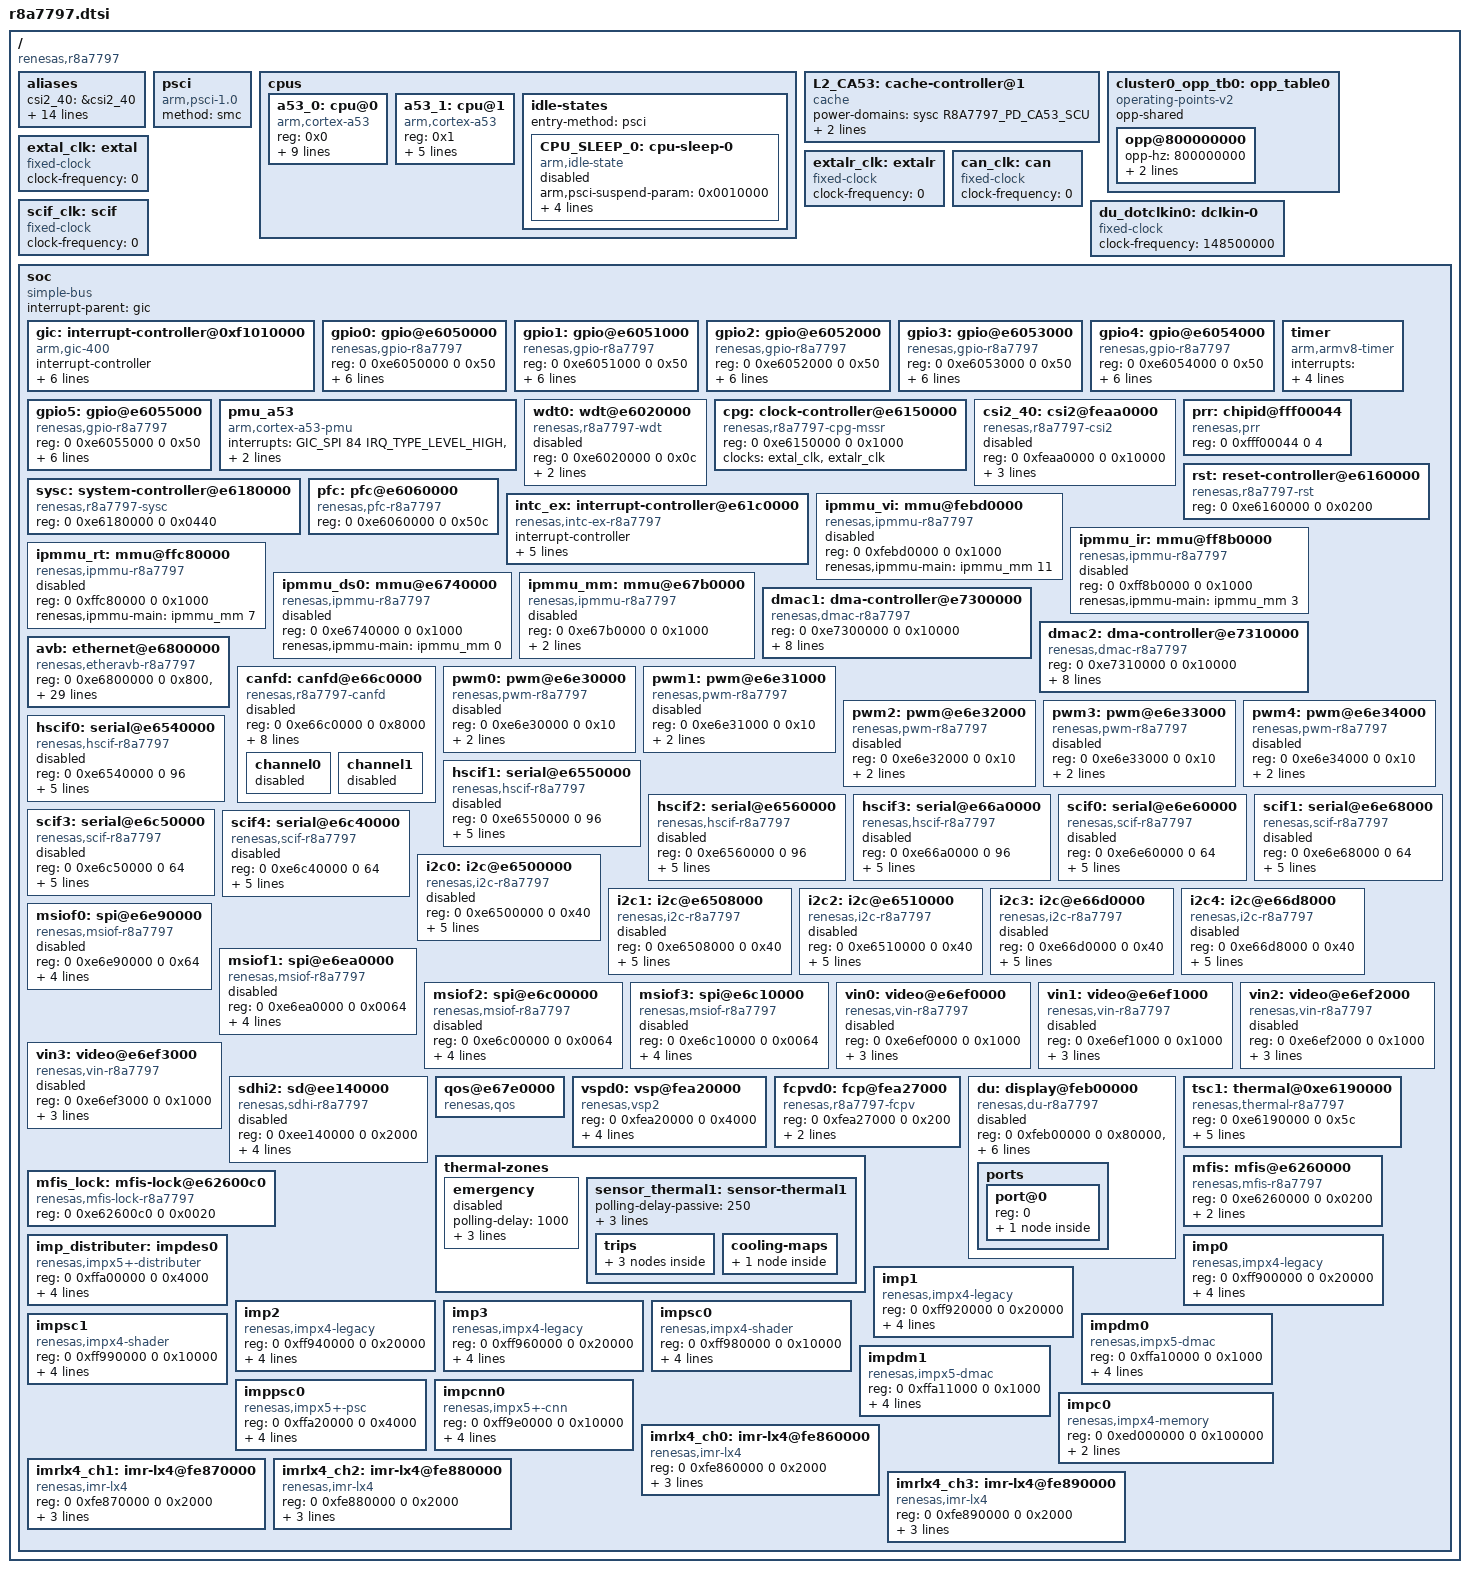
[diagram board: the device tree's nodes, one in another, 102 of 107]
/*
 * Device Tree Source for the r8a7797 SoC
 *
 * Copyright (C) 2016 - 2017 Renesas Electronics Corp.
 *
 * This file is licensed under the terms of the GNU General Public License
 * version 2.  This program is licensed "as is" without any warranty of any
 * kind, whether express or implied.
 */

#include <dt-bindings/clock/r8a7797-cpg-mssr.h>
#include <dt-bindings/interrupt-controller/arm-gic.h>
#include <dt-bindings/power/r8a7797-sysc.h>

/ {
	compatible = "renesas,r8a7797";
	#address-cells = <2>;
	#size-cells = <2>;

	aliases {
		csi2_40 = &csi2_40;
		i2c0 = &i2c0;
		i2c1 = &i2c1;
		i2c2 = &i2c2;
		i2c3 = &i2c3;
		i2c4 = &i2c4;
		spi1 = &msiof0;
		spi2 = &msiof1;
		spi3 = &msiof2;
		spi4 = &msiof3;
		vin0 = &vin0;
		vin1 = &vin1;
		vin2 = &vin2;
		vin3 = &vin3;
		tsc0 = &tsc1;
	};

	psci {
		compatible = "arm,psci-1.0";
		method = "smc";
	};

	cpus {
		#address-cells = <1>;
		#size-cells = <0>;

		a53_0: cpu@0 {
			compatible = "arm,cortex-a53", "arm,armv8";
			reg = <0x0>;
			device_type = "cpu";
			power-domains = <&sysc R8A7797_PD_CA53_CPU0>;
			next-level-cache = <&L2_CA53>;
			enable-method = "psci";
			cpu-idle-states = <&CPU_SLEEP_0>;
			#cooling-cells = <2>;
			dynamic-power-coefficient = <277>;
			cooling-min-level = <0>;
			cooling-max-level = <2>;
			clocks =<&cpg CPG_CORE R8A7797_CLK_Z2>;
			operating-points-v2 = <&cluster0_opp_tb0>;
			/*cpu-supply = <&vdd_dvfs>;*/
		};

		a53_1: cpu@1 {
			compatible = "arm,cortex-a53","arm,armv8";
			reg = <0x1>;
			device_type = "cpu";
			power-domains = <&sysc R8A7797_PD_CA53_CPU1>;
			next-level-cache = <&L2_CA53>;
			enable-method = "psci";
			cpu-idle-states = <&CPU_SLEEP_0>;
			operating-points-v2 = <&cluster0_opp_tb0>;
		};

		idle-states {
			entry-method = "psci";

			CPU_SLEEP_0: cpu-sleep-0 {
				compatible = "arm,idle-state";
				arm,psci-suspend-param = <0x0010000>;
				local-timer-stop;
				entry-latency-us = <639>;
				exit-latency-us = <680>;
				min-residency-us = <1088>;
				status = "disabled";
			};
		};
	};

	L2_CA53: cache-controller@1 {
		compatible = "cache";
		power-domains = <&sysc R8A7797_PD_CA53_SCU>;
		cache-unified;
		cache-level = <2>;
	};

	cluster0_opp_tb0: opp_table0 {
		compatible = "operating-points-v2";
		opp-shared;

		opp@800000000 {
			opp-hz = /bits/ 64 <800000000>;
			opp-microvolt = <850000>;
			clock-latency-ns = <300000>;
		};
	};

	extal_clk: extal {
		compatible = "fixed-clock";
		#clock-cells = <0>;
		/* This value must be overridden by the board */
		clock-frequency = <0>;
	};

	extalr_clk: extalr {
		compatible = "fixed-clock";
		#clock-cells = <0>;
		/* This value must be overridden by the board */
		clock-frequency = <0>;
	};

	/* External CAN clock - to be overridden by boards that provide it */
	can_clk: can {
		compatible = "fixed-clock";
		#clock-cells = <0>;
		clock-frequency = <0>;
	};

	/* External SCIF clock - to be overridden by boards that provide it */
	scif_clk: scif {
		compatible = "fixed-clock";
		#clock-cells = <0>;
		clock-frequency = <0>;
	};

	/* DU input dot clock - tob be overriden by boards that probide it */
	du_dotclkin0: dclkin-0 {
		compatible = "fixed-clock";
		#clock-cells = <0>;
		clock-frequency = <148500000>;
	};

	soc {
		compatible = "simple-bus";
		interrupt-parent = <&gic>;

		#address-cells = <2>;
		#size-cells = <2>;
		ranges;

		gic: interrupt-controller@0xf1010000 {
			compatible = "arm,gic-400";
			#interrupt-cells = <3>;
			#address-cells = <0>;
			interrupt-controller;
			reg = <0x0 0xf1010000 0 0x1000>,
			      <0x0 0xf1020000 0 0x20000>,
			      <0x0 0xf1040000 0 0x20000>,
			      <0x0 0xf1060000 0 0x20000>;
			interrupts = <GIC_PPI 9
					(GIC_CPU_MASK_SIMPLE(8) | IRQ_TYPE_LEVEL_HIGH)>;	/* PPI9:Virtual maintenance interrupt */
/*			clocks = <&cpg CPG_MOD 408>;
			clock-names = "clk";
			power-domains = <&sysc R8A7797_PD_ALWAYS_ON>; */
		};

		gpio0: gpio@e6050000 {
			compatible = "renesas,gpio-r8a7797",
				     "renesas,gpio-rcar";
			reg = <0 0xe6050000 0 0x50>;
			interrupts = <GIC_SPI 4 IRQ_TYPE_LEVEL_HIGH>;		/* SPI4:GPIO.ch0 */
			#gpio-cells = <2>;
			gpio-controller;
			gpio-ranges = <&pfc 0 0 22>;
			#interrupt-cells = <2>;
			interrupt-controller;
			clocks = <&cpg CPG_MOD 912>;				/* RMSTPCR9/bit12:GPIO0 */
			power-domains = <&sysc R8A7797_PD_ALWAYS_ON>;
		};

		gpio1: gpio@e6051000 {
			compatible = "renesas,gpio-r8a7797",
				     "renesas,gpio-rcar";
			reg = <0 0xe6051000 0 0x50>;
			interrupts = <GIC_SPI 5 IRQ_TYPE_LEVEL_HIGH>;		/* SPI5:GPIO.ch1 */
			#gpio-cells = <2>;
			gpio-controller;
			gpio-ranges = <&pfc 0 32 28>;
			#interrupt-cells = <2>;
			interrupt-controller;
			clocks = <&cpg CPG_MOD 911>;				/* RMSTPCR9/bit11:GPIO1 */
			power-domains = <&sysc R8A7797_PD_ALWAYS_ON>;
		};

		gpio2: gpio@e6052000 {
			compatible = "renesas,gpio-r8a7797",
				     "renesas,gpio-rcar";
			reg = <0 0xe6052000 0 0x50>;
			interrupts = <GIC_SPI 6 IRQ_TYPE_LEVEL_HIGH>;		/* SPI6:GPIO.ch2 */
			#gpio-cells = <2>;
			gpio-controller;
			gpio-ranges = <&pfc 0 64 17>;
			#interrupt-cells = <2>;
			interrupt-controller;
			clocks = <&cpg CPG_MOD 910>;				/* RMSTPCR9/bit10:GPIO2 */
			power-domains = <&sysc R8A7797_PD_ALWAYS_ON>;
		};

		gpio3: gpio@e6053000 {
			compatible = "renesas,gpio-r8a7797",
				     "renesas,gpio-rcar";
			reg = <0 0xe6053000 0 0x50>;
			interrupts = <GIC_SPI 7 IRQ_TYPE_LEVEL_HIGH>;		/* SPI7:GPIO.ch3 */
			#gpio-cells = <2>;
			gpio-controller;
			gpio-ranges = <&pfc 0 96 17>;
			#interrupt-cells = <2>;
			interrupt-controller;
			clocks = <&cpg CPG_MOD 909>;				/* RMSTPCR9/bit9:GPIO3 */
			power-domains = <&sysc R8A7797_PD_ALWAYS_ON>;
		};

		gpio4: gpio@e6054000 {
			compatible = "renesas,gpio-r8a7797",
				     "renesas,gpio-rcar";
			reg = <0 0xe6054000 0 0x50>;
			interrupts = <GIC_SPI 8 IRQ_TYPE_LEVEL_HIGH>;		/* SPI8:GPIO.ch4 */
			#gpio-cells = <2>;
			gpio-controller;
			gpio-ranges = <&pfc 0 128 6>;
			#interrupt-cells = <2>;
			interrupt-controller;
			clocks = <&cpg CPG_MOD 908>;				/* RMSTPCR9/bit8:GPIO4 */
			power-domains = <&sysc R8A7797_PD_ALWAYS_ON>;
		};

		gpio5: gpio@e6055000 {
			compatible = "renesas,gpio-r8a7797",
				     "renesas,gpio-rcar";
			reg = <0 0xe6055000 0 0x50>;
			interrupts = <GIC_SPI 9 IRQ_TYPE_LEVEL_HIGH>;		/* SPI9:GPIO.ch5 */
			#gpio-cells = <2>;
			gpio-controller;
			gpio-ranges = <&pfc 0 160 15>;
			#interrupt-cells = <2>;
			interrupt-controller;
			clocks = <&cpg CPG_MOD 907>;				/* RMSTPCR9/bit7:GPIO5 */
			power-domains = <&sysc R8A7797_PD_ALWAYS_ON>;
		};

		pmu_a53 {
			compatible = "arm,cortex-a53-pmu";
			interrupts = <GIC_SPI 84 IRQ_TYPE_LEVEL_HIGH>,
				     <GIC_SPI 85 IRQ_TYPE_LEVEL_HIGH>;		/* SPI84:AP-System Core.CA53core0 pmu, SPI85:AP-System Core.CA53core1 pmu */
			interrupt-affinity = <&a53_0>,
					     <&a53_1>;
		};

		timer {
			compatible = "arm,armv8-timer";
			interrupts = <GIC_PPI 13
					(GIC_CPU_MASK_SIMPLE(8) | IRQ_TYPE_LEVEL_LOW)>,
				     <GIC_PPI 14
					(GIC_CPU_MASK_SIMPLE(8) | IRQ_TYPE_LEVEL_LOW)>,
				     <GIC_PPI 11
					(GIC_CPU_MASK_SIMPLE(8) | IRQ_TYPE_LEVEL_LOW)>,
				     <GIC_PPI 10
					(GIC_CPU_MASK_SIMPLE(8) | IRQ_TYPE_LEVEL_LOW)>;	/* PPI13:Secure physical timer, PPI14:Non-secure physical timer,
																	   PPI11:Virtual timer, PPI10:Hypervisor timer */
		};

		wdt0: wdt@e6020000 {
			compatible = "renesas,r8a7797-wdt", "renesas,rcar-gen3-wdt";
			reg = <0 0xe6020000 0 0x0c>;
			clocks = <&cpg CPG_MOD 402>;					/* RMSTPCR4/bit2:RWDT */
			power-domains = <&sysc R8A7797_PD_ALWAYS_ON>;
			status = "disabled";
		};

		cpg: clock-controller@e6150000 {
			compatible = "renesas,r8a7797-cpg-mssr";
			reg = <0 0xe6150000 0 0x1000>;
			clocks = <&extal_clk>, <&extalr_clk>;
			clock-names = "extal", "extalr";
			#clock-cells = <2>;
			#power-domain-cells = <0>;
		};

		csi2_40: csi2@feaa0000 {
			compatible = "renesas,r8a7797-csi2";
			reg = <0 0xfeaa0000 0 0x10000>;
			interrupts = <GIC_SPI 246 IRQ_TYPE_LEVEL_HIGH>;		/* SPI246:CSI2.ch2 */
			clocks = <&cpg CPG_MOD 716>;				/* RMSTPCR7/bit16:CSI40 */
			power-domains = <&sysc R8A7797_PD_ALWAYS_ON>;
			status = "disabled";
		};

		prr: chipid@fff00044 {
			compatible = "renesas,prr";
			reg = <0 0xfff00044 0 4>;
		};

		rst: reset-controller@e6160000 {
			compatible = "renesas,r8a7797-rst";
			reg = <0 0xe6160000 0 0x0200>;
		};

		sysc: system-controller@e6180000 {
			compatible = "renesas,r8a7797-sysc";
			reg = <0 0xe6180000 0 0x0440>;
			#power-domain-cells = <1>;
		};

		pfc: pfc@e6060000 {
			compatible = "renesas,pfc-r8a7797";
			reg = <0 0xe6060000 0 0x50c>;
		};

		intc_ex: interrupt-controller@e61c0000 {
			compatible = "renesas,intc-ex-r8a7797", "renesas,irqc";
			#interrupt-cells = <2>;
			interrupt-controller;
			reg = <0 0xe61c0000 0 0x200>;
			interrupts = <GIC_SPI 0 IRQ_TYPE_LEVEL_HIGH
				      GIC_SPI 1 IRQ_TYPE_LEVEL_HIGH
				      GIC_SPI 2 IRQ_TYPE_LEVEL_HIGH
				      GIC_SPI 3 IRQ_TYPE_LEVEL_HIGH
				      GIC_SPI 18 IRQ_TYPE_LEVEL_HIGH
				      GIC_SPI 161 IRQ_TYPE_LEVEL_HIGH>;		/* SPI1:IRQ1, SPI2:IRQ2, SPI3:IRQ3, SPI18:IRQ4, SPI161:IRQ5 */
			clocks = <&cpg CPG_MOD 407>;				/* RMSTPCR4/bit7:INTC-EX */
			power-domains = <&sysc R8A7797_PD_ALWAYS_ON>;
		};

		ipmmu_vi: mmu@febd0000 {
			compatible = "renesas,ipmmu-r8a7797";
			reg = <0 0xfebd0000 0 0x1000>; /* IPMMU-VI */
			renesas,ipmmu-main = <&ipmmu_mm 11>;
			#iommu-cells = <1>;
			status = "disabled";
		};

		ipmmu_ir: mmu@ff8b0000 {
			compatible = "renesas,ipmmu-r8a7797";
			reg = <0 0xff8b0000 0 0x1000>; /* IPMMU-IR */
			renesas,ipmmu-main = <&ipmmu_mm 3>;
			#iommu-cells = <1>;
			status = "disabled";
		};

		ipmmu_rt: mmu@ffc80000 {
			compatible = "renesas,ipmmu-r8a7797";
			reg = <0 0xffc80000 0 0x1000>; /* IPMMU-RT */
			renesas,ipmmu-main = <&ipmmu_mm 7>;
			#iommu-cells = <1>;
			status = "disabled";
		};

		ipmmu_ds0: mmu@e6740000 {
			compatible = "renesas,ipmmu-r8a7797";
			reg = <0 0xe6740000 0 0x1000>; /* IPMMU-DS0 */
			renesas,ipmmu-main = <&ipmmu_mm 0>;
			#iommu-cells = <1>;
			status = "disabled";
		};

		ipmmu_mm: mmu@e67b0000 {
			compatible = "renesas,ipmmu-r8a7797";
			reg = <0 0xe67b0000 0 0x1000>; /* IPMMU-MM */
			interrupts = <GIC_SPI 196 IRQ_TYPE_LEVEL_HIGH>,
				     <GIC_SPI 197 IRQ_TYPE_LEVEL_HIGH>;		/* SPI196:IPMMU, SPI197:IPMMU sec */
			#iommu-cells = <1>;
			status = "disabled";
		};

		dmac1: dma-controller@e7300000 {
			compatible = "renesas,dmac-r8a7797",
				     "renesas,rcar-dmac";
			reg = <0 0xe7300000 0 0x10000>;
			interrupts = <GIC_SPI 220 IRQ_TYPE_LEVEL_HIGH
				      GIC_SPI 216 IRQ_TYPE_LEVEL_HIGH
				      GIC_SPI 217 IRQ_TYPE_LEVEL_HIGH
				      GIC_SPI 218 IRQ_TYPE_LEVEL_HIGH
				      GIC_SPI 219 IRQ_TYPE_LEVEL_HIGH
				      GIC_SPI 308 IRQ_TYPE_LEVEL_HIGH
				      GIC_SPI 309 IRQ_TYPE_LEVEL_HIGH
				      GIC_SPI 310 IRQ_TYPE_LEVEL_HIGH
				      GIC_SPI 311 IRQ_TYPE_LEVEL_HIGH>;		/* SPI220::SYS-DMAC1 err,
										   SPI216~219:SYS-DMAC1.ch0~SYS-DMAC1.ch3,
										   SPI308~311:SYS-DMAC1.ch4~SYS-DMAC1.ch7 */
			interrupt-names = "error",
					"ch0", "ch1", "ch2", "ch3",
					"ch4", "ch5", "ch6", "ch7";
			clocks = <&cpg CPG_MOD 218>;				/* RMSTPCR2/bit18:SYS-DMAC1 */
			clock-names = "fck";
			power-domains = <&sysc R8A7797_PD_ALWAYS_ON>;
			#dma-cells = <1>;
			dma-channels = <8>;
			iommus = <&ipmmu_ds0 0>, <&ipmmu_ds0 1>,
			       <&ipmmu_ds0 2>, <&ipmmu_ds0 3>,
			       <&ipmmu_ds0 4>, <&ipmmu_ds0 5>,
			       <&ipmmu_ds0 6>, <&ipmmu_ds0 7>;			/* @@ */
		};

		dmac2: dma-controller@e7310000 {
			compatible = "renesas,dmac-r8a7797",
				     "renesas,rcar-dmac";
			reg = <0 0xe7310000 0 0x10000>;
			interrupts = <GIC_SPI 307 IRQ_TYPE_LEVEL_HIGH
				      GIC_SPI 312 IRQ_TYPE_LEVEL_HIGH
				      GIC_SPI 313 IRQ_TYPE_LEVEL_HIGH
				      GIC_SPI 314 IRQ_TYPE_LEVEL_HIGH
				      GIC_SPI 315 IRQ_TYPE_LEVEL_HIGH
				      GIC_SPI 316 IRQ_TYPE_LEVEL_HIGH
				      GIC_SPI 317 IRQ_TYPE_LEVEL_HIGH
				      GIC_SPI 318 IRQ_TYPE_LEVEL_HIGH
				      GIC_SPI 319 IRQ_TYPE_LEVEL_HIGH>;		/* SPI307::SYS-DMAC2 err,
										   SPI312~319:SYS-DMAC2.ch0~SYS-DMAC1.ch7 */
			interrupt-names = "error",
					"ch0", "ch1", "ch2", "ch3",
					"ch4", "ch5", "ch6", "ch7";
			clocks = <&cpg CPG_MOD 217>;				/* RMSTPCR2/bit17:SYS-DMAC2 */
			clock-names = "fck";
			power-domains = <&sysc R8A7797_PD_ALWAYS_ON>;
			#dma-cells = <1>;
			dma-channels = <8>;
			iommus = <&ipmmu_ds0 16>, <&ipmmu_ds0 17>,
			       <&ipmmu_ds0 18>, <&ipmmu_ds0 19>,
			       <&ipmmu_ds0 20>, <&ipmmu_ds0 21>,
			       <&ipmmu_ds0 22>, <&ipmmu_ds0 23>;		/* @@ */
		};

		avb: ethernet@e6800000 {
			compatible = "renesas,etheravb-r8a7797",
				     "renesas,etheravb-rcar-gen3";
			reg = <0 0xe6800000 0 0x800>, <0 0xe6a00000 0 0x10000>;
			interrupts = <GIC_SPI 39 IRQ_TYPE_LEVEL_HIGH>,
				     <GIC_SPI 40 IRQ_TYPE_LEVEL_HIGH>,
				     <GIC_SPI 41 IRQ_TYPE_LEVEL_HIGH>,
				     <GIC_SPI 42 IRQ_TYPE_LEVEL_HIGH>,
				     <GIC_SPI 43 IRQ_TYPE_LEVEL_HIGH>,
				     <GIC_SPI 44 IRQ_TYPE_LEVEL_HIGH>,
				     <GIC_SPI 45 IRQ_TYPE_LEVEL_HIGH>,
				     <GIC_SPI 46 IRQ_TYPE_LEVEL_HIGH>,
				     <GIC_SPI 47 IRQ_TYPE_LEVEL_HIGH>,
				     <GIC_SPI 48 IRQ_TYPE_LEVEL_HIGH>,
				     <GIC_SPI 49 IRQ_TYPE_LEVEL_HIGH>,
				     <GIC_SPI 50 IRQ_TYPE_LEVEL_HIGH>,
				     <GIC_SPI 51 IRQ_TYPE_LEVEL_HIGH>,
				     <GIC_SPI 52 IRQ_TYPE_LEVEL_HIGH>,
				     <GIC_SPI 53 IRQ_TYPE_LEVEL_HIGH>,
				     <GIC_SPI 54 IRQ_TYPE_LEVEL_HIGH>,
				     <GIC_SPI 55 IRQ_TYPE_LEVEL_HIGH>,
				     <GIC_SPI 56 IRQ_TYPE_LEVEL_HIGH>,
				     <GIC_SPI 57 IRQ_TYPE_LEVEL_HIGH>,
				     <GIC_SPI 58 IRQ_TYPE_LEVEL_HIGH>,
				     <GIC_SPI 59 IRQ_TYPE_LEVEL_HIGH>,
				     <GIC_SPI 60 IRQ_TYPE_LEVEL_HIGH>,
				     <GIC_SPI 61 IRQ_TYPE_LEVEL_HIGH>,
				     <GIC_SPI 62 IRQ_TYPE_LEVEL_HIGH>,
				     <GIC_SPI 63 IRQ_TYPE_LEVEL_HIGH>;		/* SPI39~63:Ethernet AVB.ch0~24 */
										/* @@ errreq_avb_p[0]~[3] add (T.B.D) */
			interrupt-names = "ch0", "ch1", "ch2", "ch3",
					  "ch4", "ch5", "ch6", "ch7",
					  "ch8", "ch9", "ch10", "ch11",
					  "ch12", "ch13", "ch14", "ch15",
					  "ch16", "ch17", "ch18", "ch19",
					  "ch20", "ch21", "ch22", "ch23",
					  "ch24";
			clocks = <&cpg CPG_MOD 812>;				/* RMSTPCR8/bit12:EAVB-IF */
			power-domains = <&sysc R8A7797_PD_ALWAYS_ON>;
			phy-mode = "rgmii-id";
			#address-cells = <1>;
			#size-cells = <0>;
		};

		canfd: canfd@e66c0000 {
			compatible = "renesas,r8a7797-canfd",
				     "renesas,rcar-gen3-canfd";
			reg = <0 0xe66c0000 0 0x8000>;
			interrupts = <GIC_SPI 29 IRQ_TYPE_LEVEL_HIGH>,
				   <GIC_SPI 30 IRQ_TYPE_LEVEL_HIGH>;
			clocks = <&cpg CPG_MOD 914>,
			       <&cpg CPG_CORE R8A7797_CLK_CANFD>,
			       <&can_clk>;
			clock-names = "fck", "canfd", "can_clk";
			assigned-clocks = <&cpg CPG_CORE R8A7797_CLK_CANFD>;
			assigned-clock-rates = <40000000>;
			power-domains = <&sysc R8A7797_PD_ALWAYS_ON>;
			status = "disabled";

			channel0 {
				status = "disabled";
			};

			channel1 {
				status = "disabled";
			};
		};

		pwm0: pwm@e6e30000 {
			compatible = "renesas,pwm-r8a7797", "renesas,pwm-rcar";
			reg = <0 0xe6e30000 0 0x10>;
			#pwm-cells = <2>;
			clocks = <&cpg CPG_MOD 523>;				/* RMSTPCR5/bit23:PWM */
			power-domains = <&sysc R8A7797_PD_ALWAYS_ON>;
			status = "disabled";
		};

		pwm1: pwm@e6e31000 {
			compatible = "renesas,pwm-r8a7797", "renesas,pwm-rcar";
			reg = <0 0xe6e31000 0 0x10>;
			#pwm-cells = <2>;
			clocks = <&cpg CPG_MOD 523>;				/* RMSTPCR5/bit23:PWM */
			power-domains = <&sysc R8A7797_PD_ALWAYS_ON>;
			status = "disabled";
		};

		pwm2: pwm@e6e32000 {
			compatible = "renesas,pwm-r8a7797", "renesas,pwm-rcar";
			reg = <0 0xe6e32000 0 0x10>;
			#pwm-cells = <2>;
			clocks = <&cpg CPG_MOD 523>;				/* RMSTPCR5/bit23:PWM */
			power-domains = <&sysc R8A7797_PD_ALWAYS_ON>;
			status = "disabled";
		};

		pwm3: pwm@e6e33000 {
			compatible = "renesas,pwm-r8a7797", "renesas,pwm-rcar";
			reg = <0 0xe6e33000 0 0x10>;
			#pwm-cells = <2>;
			clocks = <&cpg CPG_MOD 523>;				/* RMSTPCR5/bit23:PWM */
			power-domains = <&sysc R8A7797_PD_ALWAYS_ON>;
			status = "disabled";
		};

		pwm4: pwm@e6e34000 {
			compatible = "renesas,pwm-r8a7797", "renesas,pwm-rcar";
			reg = <0 0xe6e34000 0 0x10>;
			#pwm-cells = <2>;
			clocks = <&cpg CPG_MOD 523>;				/* RMSTPCR5/bit23:PWM */
			power-domains = <&sysc R8A7797_PD_ALWAYS_ON>;
			status = "disabled";
		};

		hscif0: serial@e6540000 {
			compatible = "renesas,hscif-r8a7797",
				     "renesas,rcar-gen3-hscif",
				     "renesas,hscif";
			reg = <0 0xe6540000 0 96>;
			interrupts = <GIC_SPI 154 IRQ_TYPE_LEVEL_HIGH>;		/* SPI154:HSCIF.ch0 */
			clocks = <&cpg CPG_MOD 520>,
				 <&cpg CPG_CORE R8A7797_CLK_S2D1>,
				 <&scif_clk>;					/* RMSTPCR5/bit20:HSCIF0 */
			clock-names = "fck", "brg_int", "scif_clk";
			dmas = <&dmac1 0x31>, <&dmac1 0x30>;
			dma-names = "tx", "rx";
			power-domains = <&sysc R8A7797_PD_ALWAYS_ON>;
			status = "disabled";
		};

		hscif1: serial@e6550000 {
			compatible = "renesas,hscif-r8a7797",
				     "renesas,rcar-gen3-hscif",
				     "renesas,hscif";
			reg = <0 0xe6550000 0 96>;
			interrupts = <GIC_SPI 155 IRQ_TYPE_LEVEL_HIGH>;		/* SPI155:HSCIF.ch1 */
			clocks = <&cpg CPG_MOD 519>,
				 <&cpg CPG_CORE R8A7797_CLK_S2D1>,
				 <&scif_clk>;					/* RMSTPCR5/bit19:HSCIF1 */
			clock-names = "fck", "brg_int", "scif_clk";
			dmas = <&dmac1 0x33>, <&dmac1 0x32>;
			dma-names = "tx", "rx";
			power-domains = <&sysc R8A7797_PD_ALWAYS_ON>;
			status = "disabled";
		};

		hscif2: serial@e6560000 {
			compatible = "renesas,hscif-r8a7797",
				     "renesas,rcar-gen3-hscif",
				     "renesas,hscif";
			reg = <0 0xe6560000 0 96>;
			interrupts = <GIC_SPI 144 IRQ_TYPE_LEVEL_HIGH>;		/* SPI144:HSCIF.ch2 */
			clocks = <&cpg CPG_MOD 518>,
				 <&cpg CPG_CORE R8A7797_CLK_S2D1>,
				 <&scif_clk>;					/* RMSTPCR5/bit18:HSCIF2 */
			clock-names = "fck", "brg_int", "scif_clk";
			dmas = <&dmac1 0x35>, <&dmac1 0x34>;
			dma-names = "tx", "rx";
			power-domains = <&sysc R8A7797_PD_ALWAYS_ON>;
			status = "disabled";
		};

		hscif3: serial@e66a0000 {
			compatible = "renesas,hscif-r8a7797",
				     "renesas,rcar-gen3-hscif",
				     "renesas,hscif";
			reg = <0 0xe66a0000 0 96>;
			interrupts = <GIC_SPI 145 IRQ_TYPE_LEVEL_HIGH>;		/* SPI145:HSCIF.ch3 */
			clocks = <&cpg CPG_MOD 517>,
				 <&cpg CPG_CORE R8A7797_CLK_S2D1>,
				 <&scif_clk>;					/* RMSTPCR5/bit17:HSCIF3 */
			clock-names = "fck", "brg_int", "scif_clk";
			dmas = <&dmac1 0x37>, <&dmac1 0x36>;
			dma-names = "tx", "rx";
			power-domains = <&sysc R8A7797_PD_ALWAYS_ON>;
			status = "disabled";
		};

		scif0: serial@e6e60000 {
			compatible = "renesas,scif-r8a7797",
				     "renesas,rcar-gen3-scif", "renesas,scif";
			reg = <0 0xe6e60000 0 64>;
			interrupts = <GIC_SPI 152 IRQ_TYPE_LEVEL_HIGH>;		/* SPI152:SCIF.ch0 */
			clocks = <&cpg CPG_MOD 207>,
				 <&cpg CPG_CORE R8A7797_CLK_S2D1>,
				 <&scif_clk>;					/* RMSTPCR2/bit7:SCIF0 */
			/*clock-names = "fck", "sck", "brg_int", "scif_clk"; */
			clock-names = "fck";
			dmas = <&dmac1 0x51>, <&dmac1 0x50>;
			dma-names = "tx", "rx";
			power-domains = <&sysc R8A7797_PD_ALWAYS_ON>;
			status = "disabled";
		};

		scif1: serial@e6e68000 {
			compatible = "renesas,scif-r8a7797",
				     "renesas,rcar-gen3-scif", "renesas,scif";
			reg = <0 0xe6e68000 0 64>;
			interrupts = <GIC_SPI 153 IRQ_TYPE_LEVEL_HIGH>;		/* SPI153:SCIF.ch1 */
			clocks = <&cpg CPG_MOD 206>,
				 <&cpg CPG_CORE R8A7797_CLK_S2D1>,
				 <&scif_clk>;					/* RMSTPCR2/bit6:SCIF1 */
			clock-names = "fck", "brg_int", "scif_clk";
			dmas = <&dmac1 0x53>, <&dmac1 0x52>;
			dma-names = "tx", "rx";
			power-domains = <&sysc R8A7797_PD_ALWAYS_ON>;
			status = "disabled";
		};

		scif3: serial@e6c50000 {
			compatible = "renesas,scif-r8a7797",
				     "renesas,rcar-gen3-scif", "renesas,scif";
			reg = <0 0xe6c50000 0 64>;
			interrupts = <GIC_SPI 23 IRQ_TYPE_LEVEL_HIGH>;		/* SPI23:SCIF.ch3 */
			clocks = <&cpg CPG_MOD 204>,
				 <&cpg CPG_CORE R8A7797_CLK_S2D1>,
				 <&scif_clk>;					/* RMSTPCR2/bit4:SCIF3 */
			clock-names = "fck", "brg_int", "scif_clk";
			dmas = <&dmac1 0x57>, <&dmac1 0x56>;
			dma-names = "tx", "rx";
			power-domains = <&sysc R8A7797_PD_ALWAYS_ON>;
			status = "disabled";
		};

		scif4: serial@e6c40000 {
			compatible = "renesas,scif-r8a7797",
				     "renesas,rcar-gen3-scif", "renesas,scif";
			reg = <0 0xe6c40000 0 64>;
			interrupts = <GIC_SPI 16 IRQ_TYPE_LEVEL_HIGH>;		/* SPI16:SCIF.ch4 */
			clocks = <&cpg CPG_MOD 203>,
				 <&cpg CPG_CORE R8A7797_CLK_S2D1>,
				 <&scif_clk>;					/* RMSTPCR2/bit3:SCIF4 */
			clock-names = "fck", "brg_int", "scif_clk";
			dmas = <&dmac1 0x59>, <&dmac1 0x58>;
			dma-names = "tx", "rx";
			power-domains = <&sysc R8A7797_PD_ALWAYS_ON>;
			status = "disabled";
		};

		i2c0: i2c@e6500000 {
			#address-cells = <1>;
			#size-cells = <0>;
			compatible = "renesas,i2c-r8a7797";
			reg = <0 0xe6500000 0 0x40>;
			interrupts = <GIC_SPI 287 IRQ_TYPE_LEVEL_HIGH>;		/* SPI287:I2C.ch0 */
			clocks = <&cpg CPG_MOD 931>;				/* RMSTPCR9/bit31:I2C-IF0 */
			power-domains = <&sysc R8A7797_PD_ALWAYS_ON>;
			dmas = <&dmac1 0x91>, <&dmac1 0x90>;
			dma-names = "tx", "rx";
			i2c-scl-internal-delay-ns = <6>;
			status = "disabled";
		};

		i2c1: i2c@e6508000 {
			#address-cells = <1>;
			#size-cells = <0>;
			compatible = "renesas,i2c-r8a7797";
			reg = <0 0xe6508000 0 0x40>;
			interrupts = <GIC_SPI 288 IRQ_TYPE_LEVEL_HIGH>;		/* SPI288:I2C.ch1 */
			clocks = <&cpg CPG_MOD 930>;				/* RMSTPCR9/bit30:I2C-IF1 */
			power-domains = <&sysc R8A7797_PD_ALWAYS_ON>;
			dmas = <&dmac1 0x93>, <&dmac1 0x92>;
			dma-names = "tx", "rx";
			i2c-scl-internal-delay-ns = <6>;
			status = "disabled";
		};

		i2c2: i2c@e6510000 {
			#address-cells = <1>;
			#size-cells = <0>;
			compatible = "renesas,i2c-r8a7797";
			reg = <0 0xe6510000 0 0x40>;
			interrupts = <GIC_SPI 286 IRQ_TYPE_LEVEL_HIGH>;		/* SPI286:I2C.ch2 */
			clocks = <&cpg CPG_MOD 929>;				/* RMSTPCR9/bit29:I2C-IF2 */
			power-domains = <&sysc R8A7797_PD_ALWAYS_ON>;
			dmas = <&dmac1 0x95>, <&dmac1 0x94>;
			dma-names = "tx", "rx";
			i2c-scl-internal-delay-ns = <6>;
			status = "disabled";
		};

		i2c3: i2c@e66d0000 {
			#address-cells = <1>;
			#size-cells = <0>;
			compatible = "renesas,i2c-r8a7797";
			reg = <0 0xe66d0000 0 0x40>;
			interrupts = <GIC_SPI 290 IRQ_TYPE_LEVEL_HIGH>;		/* SPI290:I2C.ch3 */
			clocks = <&cpg CPG_MOD 928>;				/* RMSTPCR9/bit28:I2C-IF3 */
			power-domains = <&sysc R8A7797_PD_ALWAYS_ON>;
			dmas = <&dmac1 0x97>, <&dmac1 0x96>;
			dma-names = "tx", "rx";
			i2c-scl-internal-delay-ns = <6>;
			status = "disabled";
		};

		i2c4: i2c@e66d8000 {
			#address-cells = <1>;
			#size-cells = <0>;
			compatible = "renesas,i2c-r8a7797";
			reg = <0 0xe66d8000 0 0x40>;
			interrupts = <GIC_SPI 19 IRQ_TYPE_LEVEL_HIGH>;		/* SPI19:I2C.ch4 */
			clocks = <&cpg CPG_MOD 927>;				/* RMSTPCR9/bit27:I2C-IF4 */
			power-domains = <&sysc R8A7797_PD_ALWAYS_ON>;
			dmas = <&dmac1 0x99>, <&dmac1 0x98>;
			dma-names = "tx", "rx";
			i2c-scl-internal-delay-ns = <6>;
			status = "disabled";
		};

		msiof0: spi@e6e90000 {
			#address-cells = <1>;
			#size-cells = <0>;
			compatible = "renesas,msiof-r8a7797";
			reg = <0 0xe6e90000 0 0x64>;
			interrupts = <GIC_SPI 156 IRQ_TYPE_LEVEL_HIGH>;		/* SPI156:MSIOF.ch0 */
			clocks = <&cpg CPG_MOD 211>, <&msiof_ref_clk>;		/* RMSTPCR2/bit11:MSIOF0, @@ msiof_ref_clk->Eagle.dts */
			clock-names = "msiof_clk", "msiof_ref_clk";
			dmas = <&dmac1 0x41>, <&dmac1 0x40>;
			dma-names = "tx", "rx";
			power-domains = <&sysc R8A7797_PD_ALWAYS_ON>;
			status = "disabled";
		};

		msiof1: spi@e6ea0000 {
			#address-cells = <1>;
			#size-cells = <0>;
			compatible = "renesas,msiof-r8a7797";
			reg = <0 0xe6ea0000 0 0x0064>;
			interrupts = <GIC_SPI 157 IRQ_TYPE_LEVEL_HIGH>;		/* SPI157:MSIOF.ch1 */
			clocks = <&cpg CPG_MOD 210>, <&msiof_ref_clk>;		/* RMSTPCR2/bit10:MSIOF1, @@ msiof_ref_clk->Eagle.dts */
			clock-names = "msiof_clk", "msiof_ref_clk";
			dmas = <&dmac1 0x43>, <&dmac1 0x42>;
			dma-names = "tx", "rx";
			power-domains = <&sysc R8A7797_PD_ALWAYS_ON>;
			status = "disabled";
		};

		msiof2: spi@e6c00000 {
			#address-cells = <1>;
			#size-cells = <0>;
			compatible = "renesas,msiof-r8a7797";
			reg = <0 0xe6c00000 0 0x0064>;
			interrupts = <GIC_SPI 158 IRQ_TYPE_LEVEL_HIGH>;		/* SPI158:MSIOF.ch2 */
			clocks = <&cpg CPG_MOD 209>, <&msiof_ref_clk>;		/* RMSTPCR2/bit9:MSIOF2, @@ msiof_ref_clk->Eagle.dts */
			clock-names = "msiof_clk", "msiof_ref_clk";
			dmas = <&dmac1 0x45>, <&dmac1 0x44>;
			dma-names = "tx", "rx";
			power-domains = <&sysc R8A7797_PD_ALWAYS_ON>;
			status = "disabled";
		};

		msiof3: spi@e6c10000 {
			#address-cells = <1>;
			#size-cells = <0>;
			compatible = "renesas,msiof-r8a7797";
			reg = <0 0xe6c10000 0 0x0064>;
			interrupts = <GIC_SPI 159 IRQ_TYPE_LEVEL_HIGH>;		/* SPI159:MSIOF.ch3 */
			clocks = <&cpg CPG_MOD 208>, <&msiof_ref_clk>;		/* RMSTPCR2/bit8:MSIOF3, @@ msiof_ref_clk->Eagle.dts */
			clock-names = "msiof_clk", "msiof_ref_clk";
			dmas = <&dmac1 0x47>, <&dmac1 0x46>;
			dma-names = "tx", "rx";
			power-domains = <&sysc R8A7797_PD_ALWAYS_ON>;
			status = "disabled";
		};

		vin0: video@e6ef0000 {
			compatible = "renesas,vin-r8a7797";
			reg = <0 0xe6ef0000 0 0x1000>;
			interrupts = <GIC_SPI 188 IRQ_TYPE_LEVEL_HIGH>;		/* SPI188:VIN.ch0 */
			clocks = <&cpg CPG_MOD 811>;				/* RMSTPCR8/bit11:VIN0 */
			power-domains = <&sysc R8A7797_PD_ALWAYS_ON>;
			status = "disabled";
		};

		vin1: video@e6ef1000 {
			compatible = "renesas,vin-r8a7797";
			reg = <0 0xe6ef1000 0 0x1000>;
			interrupts = <GIC_SPI 189 IRQ_TYPE_LEVEL_HIGH>;		/* SPI189:VIN.ch1 */
			clocks = <&cpg CPG_MOD 810>;				/* RMSTPCR8/bit10:VIN1 */
			power-domains = <&sysc R8A7797_PD_ALWAYS_ON>;
			status = "disabled";
		};

		vin2: video@e6ef2000 {
			compatible = "renesas,vin-r8a7797";
			reg = <0 0xe6ef2000 0 0x1000>;
			interrupts = <GIC_SPI 190 IRQ_TYPE_LEVEL_HIGH>;		/* SPI190:VIN.ch2 */
			clocks = <&cpg CPG_MOD 809>;				/* RMSTPCR8/bit9:VIN2 */
			power-domains = <&sysc R8A7797_PD_ALWAYS_ON>;
			status = "disabled";
		};

		vin3: video@e6ef3000 {
			compatible = "renesas,vin-r8a7797";
			reg = <0 0xe6ef3000 0 0x1000>;
			interrupts = <GIC_SPI 191 IRQ_TYPE_LEVEL_HIGH>;		/* SPI191:VIN.ch3 */
			clocks = <&cpg CPG_MOD 808>;				/* RMSTPCR8/bit8:VIN3 */
			power-domains = <&sysc R8A7797_PD_ALWAYS_ON>;
			status = "disabled";
		};

		sdhi2: sd@ee140000 {
			compatible = "renesas,sdhi-r8a7797";
			reg = <0 0xee140000 0 0x2000>;
			interrupts = <GIC_SPI 165 IRQ_TYPE_LEVEL_HIGH>;
			clocks = <&cpg CPG_MOD 314>;
			power-domains = <&sysc R8A7797_PD_ALWAYS_ON>;
			renesas,clk-rate = <200000000>;
			status = "disabled";
		};

		qos@e67e0000 {
			compatible = "renesas,qos";
		};

		vspd0: vsp@fea20000 {
			compatible = "renesas,vsp2";
			reg = <0 0xfea20000 0 0x4000>;

			interrupts = <GIC_SPI 169 IRQ_TYPE_LEVEL_HIGH>;
			clocks = <&cpg CPG_MOD 623>;				/* RMSTPCR6/bit23:VSP(VSPD0) */
			power-domains = <&sysc R8A7797_PD_ALWAYS_ON>;

			renesas,fcp = <&fcpvd0>;
		};

		fcpvd0: fcp@fea27000 {
			compatible = "renesas,r8a7797-fcpv", "renesas,fcpv";
			reg = <0 0xfea27000 0 0x200>;
			clocks = <&cpg CPG_MOD 603>;				/* RMSTPCR6/bit3:FCPVD0 */
			power-domains = <&sysc R8A7797_PD_ALWAYS_ON>;
		};

		du: display@feb00000 {
			compatible = "renesas,du-r8a7797";
			reg = <0 0xfeb00000 0 0x80000>,
			      <0 0xfeb90000 0 0x14>;				/* LDVS */
			reg-names = "du", "lvds.0";
			interrupts = <GIC_SPI 256 IRQ_TYPE_LEVEL_HIGH>;		/* SPI256:DU.ch0 */
			clocks = <&cpg CPG_MOD 724>,
				 <&cpg CPG_MOD 727>,
				 <&dclkin_p0>;
			clock-names = "du.0", "lvds.0", "dclkin.0";
			status = "disabled";

			vsps = <&vspd0>;

			interlaced = <1>;

			ports {
				#address-cells = <1>;
				#size-cells = <0>;

				port@0 {
					reg = <0>;
					du_out_lvds0: endpoint {
					};
				};
			};
		};

		tsc1: thermal@0xe6190000 {
			compatible = "renesas,thermal-r8a7797";
			reg = <0 0xe6190000 0 0x5c>;
			interrupts = <GIC_SPI 67 IRQ_TYPE_LEVEL_HIGH>,
				     <GIC_SPI 68 IRQ_TYPE_LEVEL_HIGH>,
				     <GIC_SPI 69 IRQ_TYPE_LEVEL_HIGH>;		/* SPI67~69:Thermal Sensor.ch0~2 */
			clocks = <&cpg CPG_MOD 522>;				/* RMSTPCR5/bit22:THS/TSC */
			power-domains = <&sysc R8A7797_PD_ALWAYS_ON>;
			#thermal-sensor-cells = <0>;
			status = "okay";
		};

		thermal-zones {
			emergency {
				polling-delay = <1000>;
				on-temperature = <110000>;
				off-temperature = <95000>;
				target_cpus = <&a53_1>;
				status = "disabled";
			};

			sensor_thermal1: sensor-thermal1 {
				polling-delay-passive = <250>;
				polling-delay = <0>;
				sustainable-power = <6313>;

				/* sensor ID */
				thermal-sensors = <&tsc1>;

				trips {
					threshold: trip-point@0 {
						/* miliCelsius  */
						temperature = <90000>;
						hysteresis = <2000>;
						type = "passive";
					};

					target: trip-point@1 {
						/* miliCelsius  */
						temperature = <100000>;
						hysteresis = <2000>;
						type = "passive";
					};

					sensor1_crit: sensor1-crit {
						temperature = <120000>;
						hysteresis = <2000>;
						type = "critical";
					};
				};

				cooling-maps {
					map0 {
						trip = <&target>;
						cooling-device = <&a53_0 0 2>;
						contribution = <1024>;
					};
				};
			};
		};

		mfis: mfis@e6260000 {
			compatible = "renesas,mfis-r8a7797", "renesas,mfis";
			reg = <0 0xe6260000 0 0x0200>;
			clocks = <&cpg CPG_MOD 213>;
			clock-names = "mfis";
			interrupts = <GIC_SPI 180 IRQ_TYPE_LEVEL_HIGH>;
			interrupt-names = "eicr0";
			status = "okay";
		};

		mfis_lock: mfis-lock@e62600c0 {
			compatible =    "renesas,mfis-lock-r8a7797",
					"renesas,mfis-lock";
			reg = <0 0xe62600c0 0 0x0020>;
			status = "okay";
		};

		imp_distributer: impdes0 {
			compatible = "renesas,impx5+-distributer";
			reg = <0 0xffa00000 0 0x4000>;
			interrupts = <GIC_SPI 281 IRQ_TYPE_LEVEL_HIGH>;
			clocks = <&cpg CPG_MOD 830>;
			power-domains = <&sysc R8A7797_PD_A3IR>;
			interrupt-controller;
			#interrupt-cells = <1>;
		};

		imp0 {
			compatible = "renesas,impx4-legacy";
			reg = <0 0xff900000 0 0x20000>;
			interrupt-parent = <&imp_distributer>;
			interrupts = <0>;
			clocks = <&cpg CPG_MOD 827>;
			power-domains = <&sysc R8A7797_PD_A2IR0>;
		};

		imp1 {
			compatible = "renesas,impx4-legacy";
			reg = <0 0xff920000 0 0x20000>;
			interrupt-parent = <&imp_distributer>;
			interrupts = <1>;
			clocks = <&cpg CPG_MOD 827>;
			power-domains = <&sysc R8A7797_PD_A2IR0>;
		};

		imp2 {
			compatible = "renesas,impx4-legacy";
			reg = <0 0xff940000 0 0x20000>;
			interrupt-parent = <&imp_distributer>;
			interrupts = <2>;
			clocks = <&cpg CPG_MOD 826>;
			power-domains = <&sysc R8A7797_PD_A2IR1>;
		};

		imp3 {
			compatible = "renesas,impx4-legacy";
			reg = <0 0xff960000 0 0x20000>;
			interrupt-parent = <&imp_distributer>;
			interrupts = <3>;
			clocks = <&cpg CPG_MOD 826>;
			power-domains = <&sysc R8A7797_PD_A2IR1>;
		};

		impsc0 {
			compatible = "renesas,impx4-shader";
			reg = <0 0xff980000 0 0x10000>;
			interrupt-parent = <&imp_distributer>;
			interrupts = <4>;
			clocks = <&cpg CPG_MOD 829>;
			power-domains = <&sysc R8A7797_PD_A2SC0>;
		};

		impsc1 {
			compatible = "renesas,impx4-shader";
			reg = <0 0xff990000 0 0x10000>;
			interrupt-parent = <&imp_distributer>;
			interrupts = <5>;
			clocks = <&cpg CPG_MOD 828>;
			power-domains = <&sysc R8A7797_PD_A2SC1>;
		};

		impdm0 {
			compatible = "renesas,impx5-dmac";
			reg = <0 0xffa10000 0 0x1000>;
			interrupt-parent = <&imp_distributer>;
			interrupts = <6>;
			clocks = <&cpg CPG_MOD 825>;
			power-domains = <&sysc R8A7797_PD_A2IR2>;
		};

		impdm1 {
			compatible = "renesas,impx5-dmac";
			reg = <0 0xffa11000 0 0x1000>;
			interrupt-parent = <&imp_distributer>;
			interrupts = <7>;
			clocks = <&cpg CPG_MOD 825>;
			power-domains = <&sysc R8A7797_PD_A2IR2>;
		};

		imppsc0 {
			compatible = "renesas,impx5+-psc";
			reg = <0 0xffa20000 0 0x4000>;
			interrupt-parent = <&imp_distributer>;
			interrupts = <8>;
			clocks = <&cpg CPG_MOD 825>;
			power-domains = <&sysc R8A7797_PD_A2IR2>;
		};

		impcnn0 {
			compatible = "renesas,impx5+-cnn";
			reg = <0 0xff9e0000 0 0x10000>;
			interrupt-parent = <&imp_distributer>;
			interrupts = <9>;
			clocks = <&cpg CPG_MOD 824>;
			power-domains = <&sysc R8A7797_PD_A2IR3>;
		};

		impc0 {
			compatible = "renesas,impx4-memory";
			reg = <0 0xed000000 0 0x100000>;
			clocks = <&cpg CPG_MOD 830>;
			power-domains = <&sysc R8A7797_PD_A3IR>;
		};

		imrlx4_ch0: imr-lx4@fe860000 {
			compatible = "renesas,imr-lx4";
			reg = <0 0xfe860000 0 0x2000>;
			interrupts = <GIC_SPI 192 IRQ_TYPE_LEVEL_HIGH>;
			clocks = <&cpg CPG_MOD 823>;
			power-domains = <&sysc R8A7797_PD_ALWAYS_ON>;
		};

		imrlx4_ch1: imr-lx4@fe870000 {
			compatible = "renesas,imr-lx4";
			reg = <0 0xfe870000 0 0x2000>;
			interrupts = <GIC_SPI 193 IRQ_TYPE_LEVEL_HIGH>;
			clocks = <&cpg CPG_MOD 822>;
			power-domains = <&sysc R8A7797_PD_ALWAYS_ON>;
		};

		imrlx4_ch2: imr-lx4@fe880000 {
			compatible = "renesas,imr-lx4";
			reg = <0 0xfe880000 0 0x2000>;
			interrupts = <GIC_SPI 194 IRQ_TYPE_LEVEL_HIGH>;
			clocks = <&cpg CPG_MOD 821>;
			power-domains = <&sysc R8A7797_PD_ALWAYS_ON>;
		};

		imrlx4_ch3: imr-lx4@fe890000 {
			compatible = "renesas,imr-lx4";
			reg = <0 0xfe890000 0 0x2000>;
			interrupts = <GIC_SPI 195 IRQ_TYPE_LEVEL_HIGH>;
			clocks = <&cpg CPG_MOD 820>;
			power-domains = <&sysc R8A7797_PD_ALWAYS_ON>;
		};
	};
};
